# CY8C5888LTI_LP097 register map
File version: 0.1
CY8C58LP
Registers are 8-bit, read-write, no defined reset value unless marked. A register's access mark holds for its fields unless they carry their own. Offsets are from the block's base; lines under a group give offsets from that group; [hi:lo] are bit positions; {n}, {i} and the like mark numbered series; 'fields as' and 'values as' point back to an identical list; <NAME> marks a mode.

## Memory map
0x00000000 Base
0x00000000 Neck
0x00000000 Timer
0x00000000 RightEyebrow
0x00000000 LeftEyeball
0x00000000 LeftEyebrow
0x00000000 Eyelids
0x00000000 Lips
0x00000000 RightEyeball

## Base
Base 0x00000000
0x40006526 Base_COMPARE_1 16-bit — UDB.D0 - Assigned Compare1 Value
0x40006536 Base_COMPARE_2 16-bit — UDB.D1 - Assigned Compare2 Value
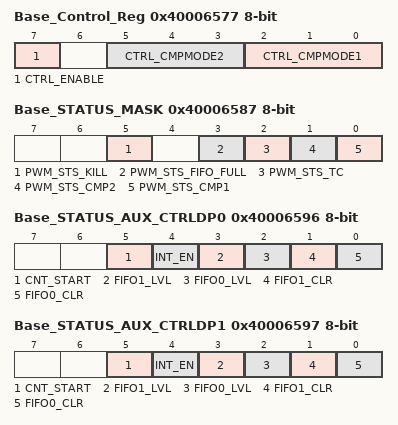
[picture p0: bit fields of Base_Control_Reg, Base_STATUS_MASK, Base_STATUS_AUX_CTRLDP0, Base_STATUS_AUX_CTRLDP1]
0x40006577 Base_Control_Reg — UDB Control Register - Assigned Control Register Value
  [7] CTRL_ENABLE — Enable the PWM
  [5:3] CTRL_CMPMODE2 — Compare mode 2
  [2:0] CTRL_CMPMODE1 — Compare mode 1
0x40006587 Base_STATUS_MASK — UDB Status bits Interrupt Mask Enable Register
  [5] PWM_STS_KILL ro — Enables the Interrupt on Kill
  [3] PWM_STS_FIFO_FULL ro — FIFO Full Status Mask
  [2] PWM_STS_TC ro — Enables the Interrupt on Terminal Count
  [1] PWM_STS_CMP2 ro — Enables the Interrupt on Compare 2
  [0] PWM_STS_CMP1 ro — Enables the Interrupt on Compare 1
0x40006596 Base_STATUS_AUX_CTRLDP0 — UDB Auxilliary Control Register
  [5] CNT_START — FIFO0 clear
    0=E_CNT_START0 (Disable counter); 1=E_CNT_START1 (Enable counter)
  [4] INT_EN
    0=E_INT_EN0 (Interrupt disabled); 1=E_INT_EN1 (Interrupt enabled)
  [3] FIFO1_LVL — FIFO level
    0=E_FIFO_LVL_0 (FIFO LVL: input mode: FIFO not full; output mode: FIFO not empty); 1=E_FIFO_LVL_1 (FIFO LVL: input mode: FIFO at least 1/2 empty; output mode: FIFO at least 1/2 full)
  [2] FIFO0_LVL — FIFO level
    values as FIFO1_LVL
  [1] FIFO1_CLR — FIFO1 clear
    0=E_FIFO_CLR_0 (Normal FIFO operation); 1=E_FIFO_CLR_1 (Clear FIFO state)
  [0] FIFO0_CLR — FIFO0 clear
    values as FIFO1_CLR
0x40006597 Base_STATUS_AUX_CTRLDP1 — UDB Auxilliary Control Register
  fields as Base_STATUS_AUX_CTRLDP0

## Neck
Base 0x00000000
0x40006524 Neck_COMPARE_1 16-bit — UDB.D0 - Assigned Compare1 Value
0x40006534 Neck_COMPARE_2 16-bit — UDB.D1 - Assigned Compare2 Value
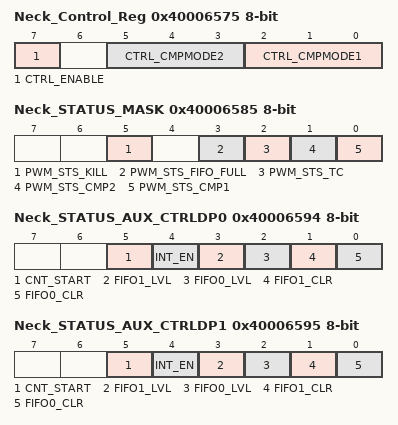
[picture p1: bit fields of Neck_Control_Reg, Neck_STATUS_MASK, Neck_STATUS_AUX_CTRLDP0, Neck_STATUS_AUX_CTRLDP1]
0x40006575 Neck_Control_Reg — UDB Control Register - Assigned Control Register Value
  [7] CTRL_ENABLE — Enable the PWM
  [5:3] CTRL_CMPMODE2 — Compare mode 2
  [2:0] CTRL_CMPMODE1 — Compare mode 1
0x40006585 Neck_STATUS_MASK — UDB Status bits Interrupt Mask Enable Register
  [5] PWM_STS_KILL ro — Enables the Interrupt on Kill
  [3] PWM_STS_FIFO_FULL ro — FIFO Full Status Mask
  [2] PWM_STS_TC ro — Enables the Interrupt on Terminal Count
  [1] PWM_STS_CMP2 ro — Enables the Interrupt on Compare 2
  [0] PWM_STS_CMP1 ro — Enables the Interrupt on Compare 1
0x40006594 Neck_STATUS_AUX_CTRLDP0 — UDB Auxilliary Control Register
  [5] CNT_START — FIFO0 clear
    0=E_CNT_START0 (Disable counter); 1=E_CNT_START1 (Enable counter)
  [4] INT_EN
    0=E_INT_EN0 (Interrupt disabled); 1=E_INT_EN1 (Interrupt enabled)
  [3] FIFO1_LVL — FIFO level
    0=E_FIFO_LVL_0 (FIFO LVL: input mode: FIFO not full; output mode: FIFO not empty); 1=E_FIFO_LVL_1 (FIFO LVL: input mode: FIFO at least 1/2 empty; output mode: FIFO at least 1/2 full)
  [2] FIFO0_LVL — FIFO level
    values as FIFO1_LVL
  [1] FIFO1_CLR — FIFO1 clear
    0=E_FIFO_CLR_0 (Normal FIFO operation); 1=E_FIFO_CLR_1 (Clear FIFO state)
  [0] FIFO0_CLR — FIFO0 clear
    values as FIFO1_CLR
0x40006595 Neck_STATUS_AUX_CTRLDP1 — UDB Auxilliary Control Register
  fields as Neck_STATUS_AUX_CTRLDP0

## Timer
Base 0x00000000
0x400043A3 Timer_GLOBAL_ENABLE — PM.ACT.CFG
  [3:0] en_timer — Enable timer/counters.
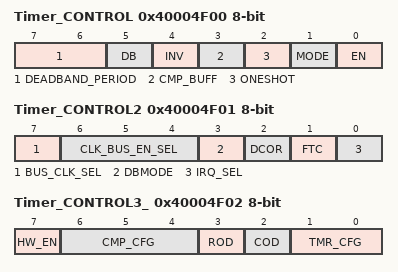
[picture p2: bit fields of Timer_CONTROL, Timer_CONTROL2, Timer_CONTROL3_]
0x40004F00 Timer_CONTROL — TMRx.CFG0
  [7:6] DEADBAND_PERIOD
  [5] DB — Deadband mode--Deadband phases phi1 and phi2 are outputted on CMP and TC output pins respectively.
    0=Timer (CMP and TC are output.); 1=Deadband (PHI1 (instead of CMP) and PHI2 (instead of TC) are output.)
  [4] INV — Invert sense of TIMEREN signal
  [3] CMP_BUFF — Buffer compare register. Compare register updates only on timer terminal count.
  [2] ONESHOT — Timer stops upon reaching stop condition defined by TMR_CFG bits. Can be restarted by asserting TIMER RESET or disabling and re-enabling block.
  [1] MODE — Mode. (0 = Timer; 1 = Comparator)
    0=Timer mode. CNT/CMP register holds timer count value.; 1=Comparator mode. CNT/CMP register holds comparator threshold value.
  [0] EN — Enables timer/comparator.
0x40004F01 Timer_CONTROL2 — TMRx.CFG1
  [7] BUS_CLK_SEL — Bus Clock selection.
  [6:4] CLK_BUS_EN_SEL — Digital Global Clock selection.
  [3] DBMODE — Deadband mode (asynchronous/synchronous). CMP output pin is also affected when not in deadband mode (CFG0.DEADBAND).
  [2] DCOR — Disable Clear on Read (DCOR) of Status Register SR0.
  [1] FTC — First Terminal Count (FTC). Setting this bit forces a single pulse on the TC pin when first enabled.
    0=Disable_FTC (Disable the single cycle pulse, which signifies the timer is starting.); 1=Enable_FTC (Enable the single cycle pulse, which signifies the timer is starting.)
  [0] IRQ_SEL — Irq selection. (0 = raw interrupts; 1 = status register interrupts)
0x40004F02 Timer_CONTROL3_ — TMRx.CFG2
  [7] HW_EN — When set Timer Enable controls counting.
  [6:4] CMP_CFG — Comparator configurations
    0=Equal (Compare Equal); 1=Less_than (Compare Less Than); 2=Less_than_or_equal (Compare Less Than or Equal .); 3=Greater (Compare Greater Than .); 4=Greater_than_or_equal (Compare Greater Than or Equal)
  [3] ROD — Reset On Disable (ROD). Resets internal state of output logic
  [2] COD — Clear On Disable (COD). Clears or gates outputs to zero.
  [1:0] TMR_CFG — Timer configuration (MODE = 0): 000 = Continuous; 001 = Pulsewidth; 010 = Period; 011 = Stop on IRQ
    0=Continuous (Timer runs while EN bit of CFG0 register is set to '1'.); 1=Pulsewidth (Timer runs from positive to negative edge of TIMEREN.); 2=Period (Timer runs from positive to positive edge of TIMEREN.); 3=Irq (Timer runs until IRQ.)
0x40004F04 Timer_PERIOD 16-bit — TMRx.PER0 - Assigned Period
0x40004F06 Timer_COUNTER 16-bit — TMRx.CNT_CMP0 - Current Down Counter Value
